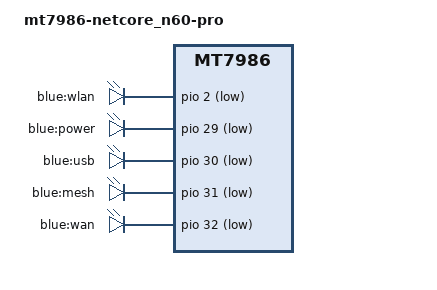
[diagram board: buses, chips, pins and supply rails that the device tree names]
// SPDX-License-Identifier: GPL-2.0

/dts-v1/;
#include "mt7986a-netcore-n60.dtsi"

/ {
	model = "mt7986-netcore_n60-pro";
	compatible = "mediatek,mt7986", "mediatek,mt7986-rfb";

	config {
		blink_led = "blue:power";
		system_led = "blue:power";
	};

	mtd-layout {
		layout@0 {
			label = "default";
			cmdline = "console=ttyS0,115200n1 loglevel=8 firmware=0 uart_en=1";
			mtdids = "nmbm0=nmbm0";
			mtdparts = "nmbm0:1024k(bl2),512k(u-boot-env),2048k(factory),2048k(fip),-(ubi)";
			boot_part = "ubi";
			factory_part = "factory";
			sysupgrade_kernel_ubipart = "fit";
			sysupgrade_rootfs_ubipart = "rootfs_data";
		};

		layout@1 {
			label = "ubootmod";
			cmdline = "console=ttyS0,115200n1 loglevel=8 firmware=0 uart_en=1";
			mtdids = "nmbm0=nmbm0";
			mtdparts = "nmbm0:1024k(bl2),512k(u-boot-env),2048k(factory),2048k(fip),-(ubi)";
			boot_part = "ubi";
			factory_part = "factory";
			sysupgrade_kernel_ubipart = "fit";
			sysupgrade_rootfs_ubipart = "rootfs_data";
		};
	};

	gpio-leds {
		compatible = "gpio-leds";

		led-0 {
			label = "blue:wlan";
			gpios = <&pio 2 GPIO_ACTIVE_LOW>;
		};

		led_power: led-1 {
			label = "blue:power";
			gpios = <&pio 29 GPIO_ACTIVE_LOW>;
		};

		led-2 {
			label = "blue:usb";
			gpios = <&pio 30 GPIO_ACTIVE_LOW>;
		};

		led-3 {
			label = "blue:mesh";
			gpios = <&pio 31 GPIO_ACTIVE_LOW>;
		};

		led-4 {
			label = "blue:wan";
			gpios = <&pio 32 GPIO_ACTIVE_LOW>;
		};
	};
};
